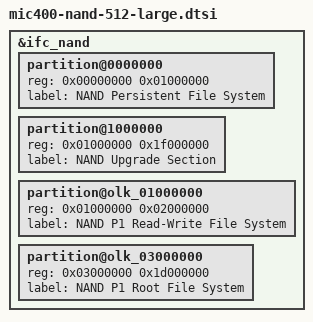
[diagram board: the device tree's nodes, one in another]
/*
 * MIC400 Device Tree Source
 *
 * Copyright 2013 OMICRON electronics GmbH.
 *
 * This program is free software; you can redistribute	it and/or modify it
 * under  the terms of	the GNU General	 Public License as published by the
 * Free Software Foundation;  either version 2 of the  License, or (at your
 * option) any later version.
 */

&ifc_nand {
	partition@0000000      { reg = <0x00000000 0x01000000>; label = "NAND Persistent File System"; };
	partition@1000000      { reg = <0x01000000 0x1f000000>; label = "NAND Upgrade Section"; };

	partition@olk_01000000 { reg = <0x01000000 0x02000000>; label = "NAND P1 Read-Write File System"; };
	partition@olk_03000000 { reg = <0x03000000 0x1d000000>; label = "NAND P1 Root File System"; };
};
